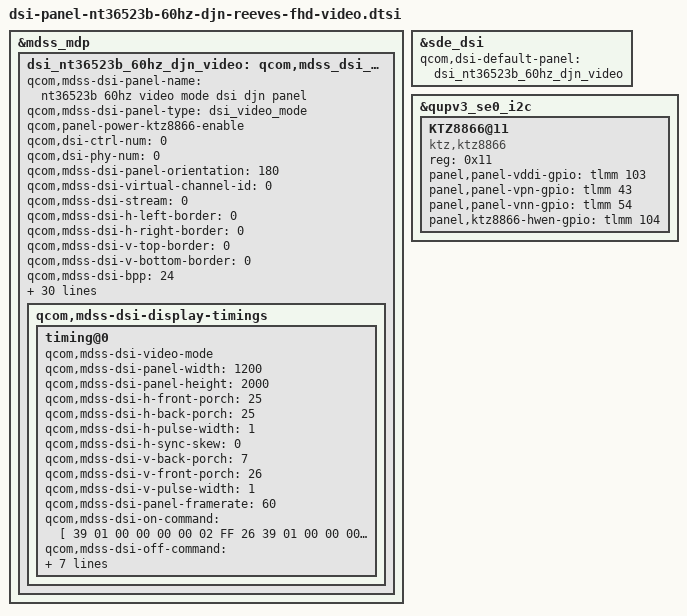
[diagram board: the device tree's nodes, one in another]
&mdss_mdp {
	dsi_nt36523b_60hz_djn_video: qcom,mdss_dsi_nt36523b_60hz_djn_video {
		qcom,mdss-dsi-panel-name =
			"nt36523b 60hz video mode dsi djn panel";
		qcom,mdss-dsi-panel-type = "dsi_video_mode";
		qcom,panel-power-ktz8866-enable;

		qcom,dsi-ctrl-num = <0>;
		qcom,dsi-phy-num = <0>;
		qcom,mdss-dsi-panel-orientation = "180";
		qcom,mdss-dsi-virtual-channel-id = <0>;
		qcom,mdss-dsi-stream = <0>;
		qcom,mdss-dsi-h-left-border = <0>;
		qcom,mdss-dsi-h-right-border = <0>;
		qcom,mdss-dsi-v-top-border = <0>;
		qcom,mdss-dsi-v-bottom-border = <0>;
		qcom,mdss-dsi-bpp = <24>;
		qcom,mdss-dsi-color-order = "rgb_swap_rgb";
		qcom,mdss-dsi-underflow-color = <0xff>;
		qcom,mdss-dsi-border-color = <0>;
		qcom,mdss-dsi-h-sync-pulse = <0>;
		qcom,mdss-dsi-traffic-mode = "non_burst_sync_event";
		qcom,mdss-dsi-lane-map = "lane_map_0123";
		qcom,mdss-dsi-bllp-eof-power-mode;
		qcom,mdss-dsi-bllp-power-mode;
		qcom,mdss-dsi-tx-eot-append;
		qcom,mdss-dsi-lane-0-state;
		qcom,mdss-dsi-lane-1-state;
		qcom,mdss-dsi-lane-2-state;
		qcom,mdss-dsi-lane-3-state;
		qcom,mdss-dsi-dma-trigger = "trigger_sw";
		qcom,mdss-dsi-mdp-trigger = "none";
		qcom,mdss-dsi-lp11-init;
		qcom,mdss-dsi-bl-pmic-control-type = "bl_ctrl_external";
		qcom,mdss-dsi-reset-sequence = <1 10>, <0 10>, <1 10>;
		qcom,mdss-pan-physical-width-dimension = <135>;
		qcom,mdss-pan-physical-height-dimension = <226>;
		qcom,mdss-dsi-display-timings {
			timing@0 {
				qcom,mdss-dsi-video-mode;
				qcom,mdss-dsi-panel-width = <1200>;
				qcom,mdss-dsi-panel-height = <2000>;
				qcom,mdss-dsi-h-front-porch = <25>;
				qcom,mdss-dsi-h-back-porch = <25>;
				qcom,mdss-dsi-h-pulse-width = <1>;
				qcom,mdss-dsi-h-sync-skew = <0>;
				qcom,mdss-dsi-v-back-porch = <7>;
				qcom,mdss-dsi-v-front-porch = <26>;
				qcom,mdss-dsi-v-pulse-width = <1>;
				qcom,mdss-dsi-panel-framerate = <60>;
				qcom,mdss-dsi-on-command = [
					39 01 00 00 00 00 02 FF 26
					39 01 00 00 00 00 02 FB 01
					39 01 00 00 00 00 02 A7 10
					39 01 00 00 00 00 02 FF 20
					39 01 00 00 00 00 02 FB 01
					39 01 00 00 00 00 02 05 B9
					39 01 00 00 00 00 02 07 5A
					39 01 00 00 00 00 02 08 5A
					39 01 00 00 00 00 02 0D 60
					39 01 00 00 00 00 02 0E 7D
					39 01 00 00 00 00 02 0F 7D
					39 01 00 00 00 00 02 1F 1A
					39 01 00 00 00 00 02 94 00
					39 01 00 00 00 00 02 95 EB
					39 01 00 00 00 00 02 96 EB
					39 01 00 00 00 00 02 9D 14
					39 01 00 00 00 00 02 9E 14
					39 01 00 00 00 00 02 58 60
					39 01 00 00 00 00 02 69 98
					39 01 00 00 00 00 02 75 A2
					39 01 00 00 00 00 02 77 B3
					39 01 00 00 00 00 02 01 52
					39 01 00 00 00 00 02 1C 74
					39 01 00 00 00 00 02 EE 70
					39 01 00 00 00 00 02 EF 70
					39 01 00 00 00 00 02 FF 20
					39 01 00 00 00 00 02 FB 01
					39 01 00 00 00 00 11 B0 00 08 00 20 00 46 00 66 00 80 00 98 00 AE 00 C1
					39 01 00 00 00 00 11 B1 00 D2 01 0E 01 39 01 7E 01 B2 02 02 02 41 02 43
					39 01 00 00 00 00 11 B2 02 7F 02 C2 02 EF 03 23 03 48 03 70 03 7F 03 8C
					39 01 00 00 00 00 0D B3 03 9B 03 AA 03 B9 03 D6 03 CF 03 CB
					39 01 00 00 00 00 11 B4 00 08 00 20 00 46 00 66 00 80 00 98 00 AE 00 C1
					39 01 00 00 00 00 11 B5 00 D2 01 0E 01 39 01 7E 01 B2 02 02 02 41 02 43
					39 01 00 00 00 00 11 B6 02 7F 02 C2 02 EF 03 23 03 48 03 70 03 7F 03 8C
					39 01 00 00 00 00 0D B7 03 9B 03 AA 03 B9 03 D6 03 CF 03 CB
					39 01 00 00 00 00 11 B8 00 08 00 20 00 46 00 66 00 80 00 98 00 AE 00 C1
					39 01 00 00 00 00 11 B9 00 D2 01 0E 01 39 01 7E 01 B2 02 02 02 41 02 43
					39 01 00 00 00 00 11 BA 02 7F 02 C2 02 EF 03 23 03 48 03 70 03 7F 03 8C
					39 01 00 00 00 00 0D BB 03 9B 03 AA 03 B9 03 D6 03 CF 03 CB
					39 01 00 00 00 00 02 C6 11
					39 01 00 00 00 00 02 C7 11
					39 01 00 00 00 00 02 C8 11
					39 01 00 00 00 00 02 C9 11
					39 01 00 00 00 00 02 CA 11
					39 01 00 00 00 00 02 CB 11
					39 01 00 00 00 00 02 CC 11
					39 01 00 00 00 00 02 CD 11
					39 01 00 00 00 00 02 CE 11
					39 01 00 00 00 00 02 CF 11
					39 01 00 00 00 00 02 D0 11
					39 01 00 00 00 00 02 D1 11
					39 01 00 00 00 00 02 D2 11
					39 01 00 00 00 00 02 D3 11
					39 01 00 00 00 00 02 D4 11
					39 01 00 00 00 00 02 D5 11
					39 01 00 00 00 00 02 D6 11
					39 01 00 00 00 00 02 D7 11
					39 01 00 00 00 00 02 D8 11
					39 01 00 00 00 00 02 D9 11
					39 01 00 00 00 00 02 DA 11
					39 01 00 00 00 00 02 DB 11
					39 01 00 00 00 00 02 DC 11
					39 01 00 00 00 00 02 DD 11
					39 01 00 00 00 00 02 DE 11
					39 01 00 00 00 00 02 DF 11
					39 01 00 00 00 00 02 E0 11
					39 01 00 00 00 00 02 E1 11
					39 01 00 00 00 00 02 E2 11
					39 01 00 00 00 00 02 E3 11
					39 01 00 00 00 00 02 FF 21
					39 01 00 00 00 00 02 FB 01
					39 01 00 00 00 00 11 B0 00 00 00 18 00 3E 00 5E 00 78 00 90 00 A6 00 B9
					39 01 00 00 00 00 11 B1 00 CA 01 06 01 31 01 76 01 AA 01 FA 02 39 02 3B
					39 01 00 00 00 00 11 B2 02 77 02 BA 02 E7 03 1B 03 40 03 68 03 77 03 84
					39 01 00 00 00 00 0D B3 03 93 03 A2 03 B1 03 CE 03 EF 03 FD
					39 01 00 00 00 00 11 B4 00 00 00 18 00 3E 00 5E 00 78 00 90 00 A6 00 B9
					39 01 00 00 00 00 11 B5 00 CA 01 06 01 31 01 76 01 AA 01 FA 02 39 02 3B
					39 01 00 00 00 00 11 B6 02 77 02 BA 02 E7 03 1B 03 40 03 68 03 77 03 84
					39 01 00 00 00 00 0D B7 03 93 03 A2 03 B1 03 CE 03 EF 03 FD
					39 01 00 00 00 00 11 B8 00 00 00 18 00 3E 00 5E 00 78 00 90 00 A6 00 B9
					39 01 00 00 00 00 11 B9 00 CA 01 06 01 31 01 76 01 AA 01 FA 02 39 02 3B
					39 01 00 00 00 00 11 BA 02 77 02 BA 02 E7 03 1B 03 40 03 68 03 77 03 84
					39 01 00 00 00 00 0D BB 03 93 03 A2 03 B1 03 CE 03 EF 03 FD
					39 01 00 00 00 00 02 FF 23
					39 01 00 00 00 00 02 FB 01
					39 01 00 00 00 00 02 10 40
					39 01 00 00 00 00 02 11 01
					39 01 00 00 00 00 02 12 77
					39 01 00 00 00 00 02 15 E0
					39 01 00 00 00 00 02 16 0C
					39 01 00 00 00 00 02 19 00
					39 01 00 00 00 00 02 1A 04
					39 01 00 00 00 00 02 1B 08
					39 01 00 00 00 00 02 1C 0C
					39 01 00 00 00 00 02 1D 10
					39 01 00 00 00 00 02 1E 14
					39 01 00 00 00 00 02 1F 18
					39 01 00 00 00 00 02 20 1C
					39 01 00 00 00 00 02 21 20
					39 01 00 00 00 00 02 22 24
					39 01 00 00 00 00 02 23 28
					39 01 00 00 00 00 02 24 2C
					39 01 00 00 00 00 02 25 30
					39 01 00 00 00 00 02 26 34
					39 01 00 00 00 00 02 27 38
					39 01 00 00 00 00 02 29 10
					39 01 00 00 00 00 02 2A 20
					39 01 00 00 00 00 02 2B 30
					39 01 00 00 00 00 02 30 F8
					39 01 00 00 00 00 02 31 F6
					39 01 00 00 00 00 02 32 F3
					39 01 00 00 00 00 02 33 F0
					39 01 00 00 00 00 02 34 EE
					39 01 00 00 00 00 02 35 EB
					39 01 00 00 00 00 02 36 E8
					39 01 00 00 00 00 02 37 E4
					39 01 00 00 00 00 02 38 E2
					39 01 00 00 00 00 02 39 E0
					39 01 00 00 00 00 02 3A DD
					39 01 00 00 00 00 02 3B D8
					39 01 00 00 00 00 02 3D D4
					39 01 00 00 00 00 02 3F D0
					39 01 00 00 00 00 02 40 CD
					39 01 00 00 00 00 02 45 EE
					39 01 00 00 00 00 02 46 EB
					39 01 00 00 00 00 02 47 E6
					39 01 00 00 00 00 02 48 D3
					39 01 00 00 00 00 02 49 D0
					39 01 00 00 00 00 02 4A CD
					39 01 00 00 00 00 02 4B C8
					39 01 00 00 00 00 02 4C C3
					39 01 00 00 00 00 02 4D C0
					39 01 00 00 00 00 02 4E BD
					39 01 00 00 00 00 02 4F BB
					39 01 00 00 00 00 02 50 B4
					39 01 00 00 00 00 02 51 B0
					39 01 00 00 00 00 02 52 AD
					39 01 00 00 00 00 02 53 A8
					39 01 00 00 00 00 02 54 A4
					39 01 00 00 00 00 02 FF 20
					39 01 00 00 00 00 02 FB 01
					39 01 00 00 00 00 02 A0 02
					39 01 00 00 00 00 02 FF 23
					39 01 00 00 00 00 02 FB 01
					39 01 00 00 00 00 02 00 80
					39 01 00 00 00 00 02 07 00
					39 01 00 00 00 00 02 08 01
					39 01 00 00 00 00 02 09 2C
					39 01 00 00 0A 00 02 FF 24
					39 01 00 00 00 00 02 FB 01
					39 01 00 00 00 00 02 91 44
					39 01 00 00 00 00 02 92 80
					39 01 00 00 00 00 02 93 1A
					39 01 00 00 00 00 02 94 5B
					39 01 00 00 00 00 02 9A 08
					39 01 00 00 00 00 02 60 96
					39 01 00 00 00 00 02 61 D0
					39 01 00 00 00 00 02 63 70
					39 01 00 00 00 00 02 C2 C6
					39 01 00 00 00 00 02 00 03
					39 01 00 00 00 00 02 01 03
					39 01 00 00 00 00 02 02 03
					39 01 00 00 00 00 02 03 03
					39 01 00 00 00 00 02 04 03
					39 01 00 00 00 00 02 05 03
					39 01 00 00 00 00 02 06 03
					39 01 00 00 00 00 02 07 03
					39 01 00 00 00 00 02 08 22
					39 01 00 00 00 00 02 09 06
					39 01 00 00 00 00 02 0A 05
					39 01 00 00 00 00 02 0B 1D
					39 01 00 00 00 00 02 0C 1C
					39 01 00 00 00 00 02 0D 11
					39 01 00 00 00 00 02 0E 10
					39 01 00 00 00 00 02 0F 0F
					39 01 00 00 00 00 02 10 0E
					39 01 00 00 00 00 02 11 0D
					39 01 00 00 00 00 02 12 0C
					39 01 00 00 00 00 02 13 04
					39 01 00 00 00 00 02 14 03
					39 01 00 00 00 00 02 15 00
					39 01 00 00 00 00 02 16 03
					39 01 00 00 00 00 02 17 03
					39 01 00 00 00 00 02 18 03
					39 01 00 00 00 00 02 19 03
					39 01 00 00 00 00 02 1A 03
					39 01 00 00 00 00 02 1B 03
					39 01 00 00 00 00 02 1C 03
					39 01 00 00 00 00 02 1D 03
					39 01 00 00 00 00 02 1E 22
					39 01 00 00 00 00 02 1F 06
					39 01 00 00 00 00 02 20 05
					39 01 00 00 00 00 02 21 1D
					39 01 00 00 00 00 02 22 1C
					39 01 00 00 00 00 02 23 11
					39 01 00 00 00 00 02 24 10
					39 01 00 00 00 00 02 25 0F
					39 01 00 00 00 00 02 26 0E
					39 01 00 00 00 00 02 27 0D
					39 01 00 00 00 00 02 28 0C
					39 01 00 00 00 00 02 29 04
					39 01 00 00 00 00 02 2A 03
					39 01 00 00 00 00 02 2B 03
					39 01 00 00 00 00 02 2F 04
					39 01 00 00 00 00 02 30 32
					39 01 00 00 00 00 02 31 41
					39 01 00 00 00 00 02 33 32
					39 01 00 00 00 00 02 34 04
					39 01 00 00 00 00 02 35 41
					39 01 00 00 00 00 02 37 44
					39 01 00 00 00 00 02 38 40
					39 01 00 00 00 00 02 39 00
					39 01 00 00 00 00 02 3A 01
					39 01 00 00 00 00 02 3B 4E
					39 01 00 00 00 00 02 3D 93
					39 01 00 00 00 00 02 AB 44
					39 01 00 00 00 00 02 AC 44
					39 01 00 00 00 00 02 4D 21
					39 01 00 00 00 00 02 4E 43
					39 01 00 00 00 00 02 4F 65
					39 01 00 00 00 00 02 51 34
					39 01 00 00 00 00 02 52 12
					39 01 00 00 00 00 02 53 56
					39 01 00 00 00 00 03 55 83 03
					39 01 00 00 00 00 02 56 06
					39 01 00 00 00 00 02 58 21
					39 01 00 00 00 00 02 59 40
					39 01 00 00 00 00 02 5A 01
					39 01 00 00 00 00 02 5B 4E
					39 01 00 00 00 00 03 5E 00 0C
					39 01 00 00 00 00 02 5F 00
					39 01 00 00 00 00 02 5C 88
					39 01 00 00 00 00 02 5D 08
					39 01 00 00 00 00 02 8D 88
					39 01 00 00 00 00 02 8E 08
					39 01 00 00 00 00 02 7A 00
					39 01 00 00 00 00 02 7B 00
					39 01 00 00 00 00 02 7C 00
					39 01 00 00 00 00 02 7D 00
					39 01 00 00 00 00 02 7E 20
					39 01 00 00 00 00 02 7F 3C
					39 01 00 00 00 00 02 80 00
					39 01 00 00 00 00 02 81 00
					39 01 00 00 00 00 02 82 08
					39 01 00 00 00 00 02 97 02
					39 01 00 00 00 00 02 D7 55
					39 01 00 00 00 00 02 D8 55
					39 01 00 00 00 00 02 D9 23
					39 01 00 00 00 00 02 DA 05
					39 01 00 00 00 00 02 DB 01
					39 01 00 00 00 00 02 DC 80
					39 01 00 00 00 00 02 DD 55
					39 01 00 00 00 00 02 DE 27
					39 01 00 00 00 00 02 DF 01
					39 01 00 00 00 00 02 E0 80
					39 01 00 00 00 00 02 E1 01
					39 01 00 00 00 00 02 E2 80
					39 01 00 00 00 00 02 E3 01
					39 01 00 00 00 00 02 E4 80
					39 01 00 00 00 00 02 E5 01
					39 01 00 00 00 00 02 E6 80
					39 01 00 00 00 00 02 E7 00
					39 01 00 00 00 00 02 E8 00
					39 01 00 00 00 00 02 E9 01
					39 01 00 00 00 00 02 EA 80
					39 01 00 00 00 00 02 EB 01
					39 01 00 00 00 00 02 EE 80
					39 01 00 00 00 00 02 EF 01
					39 01 00 00 00 00 02 F0 80
					39 01 00 00 00 00 02 C5 10
					39 01 00 00 0A 00 02 FF 25
					39 01 00 00 00 00 02 FB 01
					39 01 00 00 00 00 02 1E 00
					39 01 00 00 00 00 02 1F 01
					39 01 00 00 00 00 02 20 4E
					39 01 00 00 00 00 02 25 00
					39 01 00 00 00 00 02 26 01
					39 01 00 00 00 00 02 27 4E
					39 01 00 00 00 00 02 3F 80
					39 01 00 00 00 00 02 40 00
					39 01 00 00 00 00 02 43 00
					39 01 00 00 00 00 02 44 01
					39 01 00 00 00 00 02 45 4E
					39 01 00 00 00 00 02 48 01
					39 01 00 00 00 00 02 49 4E
					39 01 00 00 00 00 02 5B 80
					39 01 00 00 00 00 02 5C 00
					39 01 00 00 00 00 02 5D 01
					39 01 00 00 00 00 02 5E 4E
					39 01 00 00 00 00 02 61 01
					39 01 00 00 00 00 02 62 4E
					39 01 00 00 00 00 02 68 0C
					39 01 00 00 0A 00 02 FF 26
					39 01 00 00 00 00 02 FB 01
					39 01 00 00 00 00 02 01 30
					39 01 00 00 00 00 02 00 A1
					39 01 00 00 00 00 02 02 31
					39 01 00 00 00 00 02 04 28
					39 01 00 00 00 00 02 0A F3
					39 01 00 00 00 00 02 06 32
					39 01 00 00 00 00 02 0C 11
					39 01 00 00 00 00 02 0D 00
					39 01 00 00 00 00 02 0F 09
					39 01 00 00 00 00 02 11 00
					39 01 00 00 00 00 02 12 50
					39 01 00 00 00 00 02 13 6C
					39 01 00 00 00 00 02 14 6C
					39 01 00 00 00 00 02 15 00
					39 01 00 00 00 00 02 16 90
					39 01 00 00 00 00 02 17 A0
					39 01 00 00 00 00 02 18 86
					39 01 00 00 00 00 02 19 15
					39 01 00 00 00 00 02 1A 00
					39 01 00 00 00 00 02 1B 15
					39 01 00 00 00 00 02 1C 00
					39 01 00 00 00 00 02 2A 15
					39 01 00 00 00 00 02 2B 00
					39 01 00 00 00 00 02 1D 00
					39 01 00 00 00 00 02 1E 80
					39 01 00 00 00 00 02 1F 80
					39 01 00 00 00 00 02 2F 05
					39 01 00 00 00 00 02 30 80
					39 01 00 00 00 00 02 33 11
					39 01 00 00 00 00 02 34 78
					39 01 00 00 00 00 02 35 16
					39 01 00 00 00 00 02 39 0C
					39 01 00 00 00 00 02 3A 80
					39 01 00 00 00 00 02 3B 06
					39 01 00 00 00 00 02 C8 04
					39 01 00 00 00 00 02 C9 08
					39 01 00 00 00 00 02 CA 4E
					39 01 00 00 00 00 02 CB 00
					39 01 00 00 00 00 02 A9 79
					39 01 00 00 00 00 02 AA 74
					39 01 00 00 00 00 02 AB 6F
					39 01 00 00 00 00 02 AC 6D
					39 01 00 00 00 00 02 AD 71
					39 01 00 00 00 00 02 AE 80
					39 01 00 00 00 00 02 AF 7E
					39 01 00 00 00 00 02 B0 77
					39 01 00 00 00 00 02 B1 79
					39 01 00 00 00 00 02 B2 80
					39 01 00 00 0A 00 02 FF 27
					39 01 00 00 00 00 02 FB 01
					39 01 00 00 00 00 02 14 52
					39 01 00 00 00 00 02 D1 24
					39 01 00 00 00 00 02 D2 30
					39 01 00 00 00 00 02 C0 18
					39 01 00 00 00 00 02 C1 00
					39 01 00 00 00 00 02 C2 00
					39 01 00 00 00 00 02 56 06
					39 01 00 00 00 00 02 58 00
					39 01 00 00 00 00 02 59 46
					39 01 00 00 00 00 02 5A 00
					39 01 00 00 00 00 02 5B 13
					39 01 00 00 00 00 02 5C 00
					39 01 00 00 00 00 02 5D 01
					39 01 00 00 00 00 02 5E 20
					39 01 00 00 00 00 02 5F 10
					39 01 00 00 00 00 02 60 00
					39 01 00 00 00 00 02 61 11
					39 01 00 00 00 00 02 62 00
					39 01 00 00 00 00 02 63 01
					39 01 00 00 00 00 02 64 21
					39 01 00 00 00 00 02 65 0F
					39 01 00 00 00 00 02 66 00
					39 01 00 00 00 00 02 67 01
					39 01 00 00 00 00 02 68 22
					39 01 00 00 00 00 02 98 01
					39 01 00 00 00 00 02 B4 03
					39 01 00 00 00 00 02 9B BE
					39 01 00 00 00 00 02 9C 00
					39 01 00 00 00 00 02 A0 15
					39 01 00 00 00 00 02 AB 14
					39 01 00 00 00 00 02 AC 00
					39 01 00 00 00 00 02 B0 83
					39 01 00 00 00 00 02 BC 10
					39 01 00 00 00 00 02 BD 28
					39 01 00 00 0A 00 02 FF 2A
					39 01 00 00 00 00 02 FB 01
					39 01 00 00 00 00 02 F1 00
					39 01 00 00 00 00 02 22 2F
					39 01 00 00 00 00 02 23 08
					39 01 00 00 00 00 02 24 00
					39 01 00 00 00 00 02 25 7F
					39 01 00 00 00 00 02 26 F8
					39 01 00 00 00 00 02 27 00
					39 01 00 00 00 00 02 28 1A
					39 01 00 00 00 00 02 29 00
					39 01 00 00 00 00 02 2A 1A
					39 01 00 00 00 00 02 2B 00
					39 01 00 00 00 00 02 2D 1A
					39 01 00 00 00 00 02 64 96
					39 01 00 00 00 00 02 65 00
					39 01 00 00 00 00 02 66 00
					39 01 00 00 00 00 02 6A 96
					39 01 00 00 00 00 02 6B 00
					39 01 00 00 00 00 02 6C 00
					39 01 00 00 00 00 02 70 92
					39 01 00 00 00 00 02 71 00
					39 01 00 00 00 00 02 72 00
					39 01 00 00 00 00 02 A2 33
					39 01 00 00 00 00 02 A3 30
					39 01 00 00 00 00 02 A4 C0
					39 01 00 00 00 00 02 E8 00
					39 01 00 00 00 00 02 FF F0
					39 01 00 00 00 00 02 FB 01
					39 01 00 00 00 00 02 00 33
					39 01 00 00 00 00 02 FF F0
					39 01 00 00 00 00 02 FB 01
					39 01 00 00 00 00 02 84 08
					39 01 00 00 00 00 02 85 0C
					39 01 00 00 00 00 02 FF 20
					39 01 00 00 00 00 02 FB 01
					39 01 00 00 00 00 02 30 00
					39 01 00 00 00 00 02 51 00
					39 01 00 00 00 00 02 FF 25
					39 01 00 00 00 00 02 FB 01
					39 01 00 00 00 00 02 91 1F
					39 01 00 00 00 00 02 92 0F
					39 01 00 00 00 00 02 93 01
					39 01 00 00 00 00 02 94 18
					39 01 00 00 00 00 02 95 03
					39 01 00 00 00 00 02 96 01
					39 01 00 00 0A 00 02 FF 10
					39 01 00 00 00 00 02 B9 01
					39 01 00 00 0A 00 02 FF 20
					39 01 00 00 00 00 02 18 40
					39 01 00 00 0A 00 02 FF 10
					39 01 00 00 00 00 02 B9 02
					39 01 00 00 0A 00 02 FF 10
					39 01 00 00 00 00 02 FB 01
					39 01 00 00 00 00 02 BB 13
					39 01 00 00 00 00 02 53 2C
					39 01 00 00 00 00 03 68 02 01
					39 01 00 00 00 00 06 3B 03 08 1A 04 04
					39 01 00 00 00 00 02 35 00
					05 01 00 00 64 00 02 11 00
					05 01 00 00 0A 00 02 29 00];
				qcom,mdss-dsi-off-command = [
					05 01 00 00 14 00 02 28 00
					05 01 00 00 78 00 02 10 00];
				qcom,mdss-dsi-on-command-state = "dsi_lp_mode";
				qcom,mdss-dsi-off-command-state = "dsi_hs_mode";
			};
		};
	};
};

&dsi_nt36523b_60hz_djn_video {
	qcom,mdss-dsi-bl-pmic-control-type = "bl_ctrl_external";
	qcom,mdss-dsi-bl-min-level = <1>;
	qcom,mdss-dsi-bl-max-level = <2047>;
	qcom,mdss-brightness-max-level = <2047>;
	qcom,mdss-brightness-min-level = <1>;
	qcom,platform-te-gpio = <&tlmm 81 0>;
	qcom,platform-reset-gpio = <&tlmm 82 0>;
};

&dsi_nt36523b_60hz_djn_video {
	qcom,dsi-select-clocks = "mux_byte_clk0", "mux_pixel_clk0";
    qcom,mdss-dsi-display-timings {
        timing@0 {
			qcom,mdss-dsi-panel-phy-timings =
					[00 1F 08 07 18 22 08
					08 08 02 04 00 1A 0D];
            qcom,display-topology = <1 0 1>;
            qcom,default-topology-index = <0>;
        };
    };
};

&sde_dsi {
	qcom,dsi-default-panel = <&dsi_nt36523b_60hz_djn_video>;
};

&qupv3_se0_i2c {
	KTZ8866@11 {
		compatible = "ktz,ktz8866";
		reg = <0x11>;
		panel,panel-vddi-gpio = <&tlmm 103 0>;
		panel,panel-vpn-gpio = <&tlmm 43 0>;
		panel,panel-vnn-gpio = <&tlmm 54 0>;
		panel,ktz8866-hwen-gpio = <&tlmm 104 0>;
	};
};
